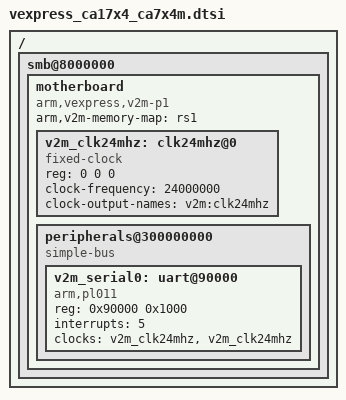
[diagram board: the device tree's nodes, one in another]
/*
 * SPDX-License-Identifier: Apache-2.0
 * Copyright (c) 2019 KapaXL (kapa.xl@outlook.com)
 *
 * FVP Motherboard component
 */

/ {
	smb@8000000 {
		motherboard {
			arm,v2m-memory-map = "rs1";
			compatible = "arm,vexpress,v2m-p1", "simple-bus";
			#address-cells = <2>;
			#size-cells = <1>;
			ranges;

			v2m_clk24mhz: clk24mhz@0 {
				compatible = "fixed-clock";
				#clock-cells = <0>;
				reg = <0 0 0>;
				clock-frequency = <24000000>;
				clock-output-names = "v2m:clk24mhz";
			};

			peripherals@300000000 {
				compatible = "simple-bus";
				#address-cells = <1>;
				#size-cells = <1>;
				ranges = <0 3 0 0x200000>;
				v2m_serial0: uart@90000 {
					compatible = "arm,pl011", "arm,primecell";
					reg = <0x90000 0x1000>;
					interrupts = <5>;
					clocks = <&v2m_clk24mhz>, <&v2m_clk24mhz>;
					clock-names = "uartclk", "apb_pclk";
				};
			};
		};
	};
};
